# N32H7xx register map
Vendor: Nationstech Ltd.; File version: 1.0
CPU: CM7 r1p1, little endian, MPU, FPU, 4 interrupt priority bits
Registers are 32-bit, read-write, reset 0x0 unless marked. A register's access mark holds for its fields unless they carry their own. Offsets are from the block's base; [hi:lo] are bit positions.

## H2P — Host to peripherals
Base 0x50070400
Same registers: P2H 0x50090400
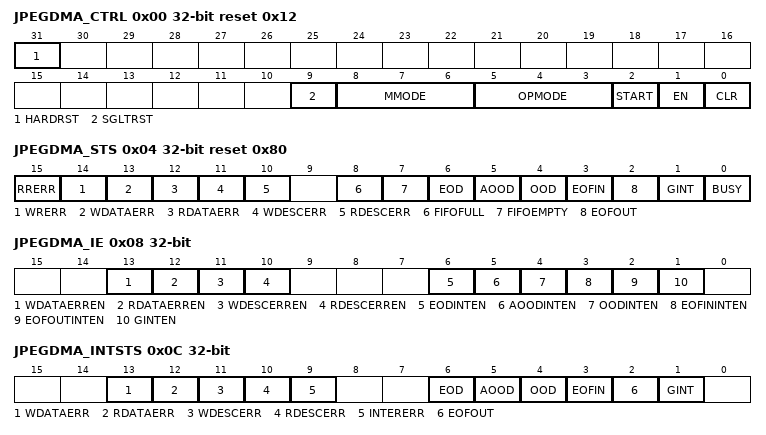
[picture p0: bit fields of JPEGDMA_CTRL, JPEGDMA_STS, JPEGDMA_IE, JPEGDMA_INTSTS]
0x00 JPEGDMA_CTRL reset 0x12 — Complex register controlling the Core��s execution and setting the various configurations.
  [31] HARDRST, [9] SGLTRST, [8:6] MMODE, [5:3] OPMODE, [2] START, [1] EN, [0] CLR
0x04 JPEGDMA_STS reset 0x80 — Complex register reporting the status of the Core.
  [15] RRERR ro, [14] WRERR ro, [13] WDATAERR ro, [12] RDATAERR ro, [11] WDESCERR ro, [10] RDESCERR ro, [8] FIFOFULL ro, [7] FIFOEMPTY ro, [6] EOD write-1-clears, [5] AOOD write-1-clears, [4] OOD write-1-clears, [3] EOFIN write-1-clears, [2] EOFOUT write-1-clears, [1] GINT ro, [0] BUSY ro
0x08 JPEGDMA_IE — Masks the Status Register to select which interrupts are visible by the host.
  [13] WDATAERREN, [12] RDATAERREN, [11] WDESCERREN, [10] RDESCERREN, [6] EODINTEN, [5] AOODINTEN, [4] OODINTEN, [3] EOFININTEN, [2] EOFOUTINTEN, [1] GINTEN
0x0C JPEGDMA_INTSTS ro — Interrupt Status Register �C contains bitwise AND of the Status Register and the Interrupt Control Register.
  [13] WDATAERR, [12] RDATAERR, [11] WDESCERR, [10] RDESCERR, [9] INTERERR, [6] EOD, [5] AOOD, [4] OOD, [3] EOFIN, [2] EOFOUT, [1] GINT
0x10 JPEGDMA_AOODT — Almost Out Of Descriptors Threshold. The register defines a remaining descriptor number threshold below which the core asserts INT_AOOD interrupt when enabled. A value of 0 disables the threshold.
  [31:0] AOODTHR — VALUE
0x14 JPEGDMA_MBSIZE reset 0x100 — Maximum allowed size for an AXI4 MM burst. The value must be smaller than the DATA_FIFO_DEPTH. Maximum permissible value calculated from the interface��s data width according to AXI4 specifications.
  [31:0] MAXBSIZE — SIZE
0x18 JPEGDMA_SGLPL — Scatter-Gather List Pointer. The register defines the base address of the channel��s Scatter-Gather list in host memory. Field should be updated before SGList SIZE and SGList HEAD.
  [31:0] ADDR
0x1C JPEGDMA_SGLPM — Scatter-Gather List Pointer. The register defines the upper 32 bits of the 64-bit base address of the channel��s Scatter Gather list in host memory. Field should be updated before SGList SIZE and SGList HEAD.
  [31:0] ADDR
0x20 JPEGDMA_SGLSIZE — Scatter-Gather List Size. The register defines the number of Descriptors in the Scatter-Gather list/ring (16-bit).
  [31:0] SGLSIZE — SIZE
0x24 JPEGDMA_SGLHEAD — Scatter-Gather List Head index pointer defines the position of the Head pointer in the list/ring. The values are integers interpreted as 1st, 2nd, etc. Descriptor and not as addresses.
  [31:0] POS
0x28 JPEGDMA_SGLTAIL — Scatter-Gather List Tail index pointer in the list/ring. The values are integers interpreted as 1st, 2nd, etc. Descriptor and not as addresses.
  [31:0] POS
0x2C JPEGDMA_MRADDL ro — AXI Memory Read Address reports the current address of the AXI MM interface��s read channel accesses. The value is used for debugging and error reporting.
  [31:0] ADDR
0x30 JPEGDMA_MRADDM ro — AXI Memory Read Address - upper 32 bits in case of 64-bit addresses.
  [31:0] ADDR
0x34 JPEGDMA_MWADDL ro — AXI Memory Write Address reports the current address of the AXI MM interface��s write channel accesses. The value is used for debugging and error reporting.
  [31:0] ADDR
0x38 JPEGDMA_MWADDM ro — AXI Memory Write Address - upper 32 bits in case of 64-bit addresses.
  [31:0] ADDR
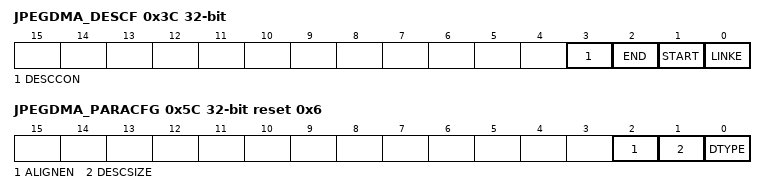
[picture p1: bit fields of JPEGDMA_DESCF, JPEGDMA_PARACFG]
0x3C JPEGDMA_DESCF — Descriptor Flag bits:
  [3] DESCCON, [2] END, [1] START, [0] LINKE
0x40 JPEGDMA_DESC_MBSIZE — Descriptor Memory Block Size. Total allocated size of memory space the descriptor points to.
  [31:0] SIZE
0x44 JPEGDMA_DESC_MUS ro — Descriptor Memory Used Space. Size of memory space utilized (field use when peripheral writes data to the host memory).
  [31:0] SIZE
0x48 JPEGDMA_DESC_MBADDL — Descriptor Memory Block Address. The starting address of the data block in host memory that this descriptor refers to.
  [31:0] ADDR
0x4C JPEGDMA_DESC_MBADDM — Descriptor Memory Block Address - upper 32 bits of the 64-bit addresses.
  [31:0] ADDR
0x54 JPEGDMA_DESC_LINKL — Descriptor Link Address - link to the next descriptor. Used when Link Enable = 1.
  [31:0] ADDR
0x58 JPEGDMA_DESC_LINKM — Descriptor Link Address - upper 32 bits of the 64-bit addresses.
  [31:0] ADDR
0x5C JPEGDMA_PARACFG ro reset 0x6 — Field mirroring the Configuration Parameters
  [2] ALIGNEN, [1] DESCSIZE, [0] DTYPE
0x60 JPEGDMA_FIFODP ro reset 0x100 — Field mirroring the DATA_FIFO_DEPTH parameter.
  [31:0] DEPTH
